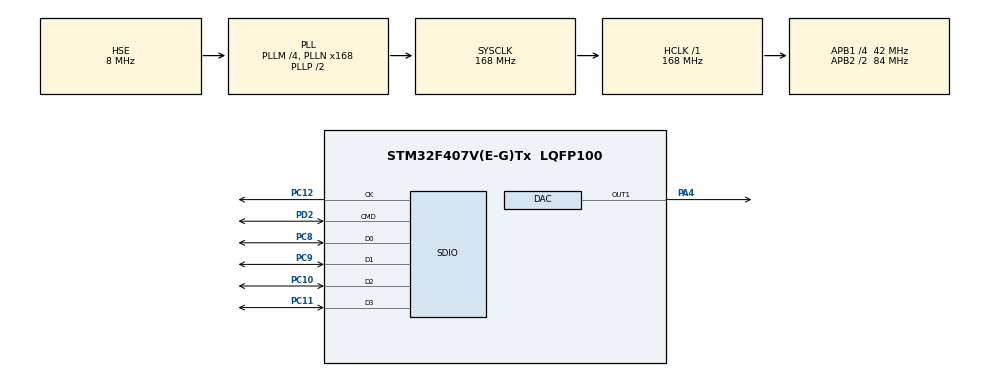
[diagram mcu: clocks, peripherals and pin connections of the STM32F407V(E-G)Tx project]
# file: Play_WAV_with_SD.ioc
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DAC.DAC_Trigger=DAC_TRIGGER_T6_TRGO
Dma.DAC1.0.Direction=DMA_MEMORY_TO_PERIPH
Dma.DAC1.0.FIFOMode=DMA_FIFOMODE_DISABLE
Dma.DAC1.0.Instance=DMA1_Stream5
Dma.DAC1.0.MemDataAlignment=DMA_MDATAALIGN_HALFWORD
Dma.DAC1.0.MemInc=DMA_MINC_ENABLE
Dma.DAC1.0.Mode=DMA_NORMAL
Dma.DAC1.0.PeriphDataAlignment=DMA_PDATAALIGN_HALFWORD
Dma.DAC1.0.PeriphInc=DMA_PINC_DISABLE
Dma.DAC1.0.Priority=DMA_PRIORITY_LOW
Dma.Request0=DAC1
Dma.Request1=SDIO_RX
Dma.SDIO_RX.1.Direction=DMA_PERIPH_TO_MEMORY
Dma.SDIO_RX.1.FIFOMode=DMA_FIFOMODE_ENABLE
Dma.SDIO_RX.1.FIFOThreshold=DMA_FIFO_THRESHOLD_FULL
Dma.SDIO_RX.1.Instance=DMA2_Stream3
Dma.SDIO_RX.1.MemBurst=DMA_MBURST_INC4
Dma.SDIO_RX.1.MemDataAlignment=DMA_MDATAALIGN_WORD
Dma.SDIO_RX.1.MemInc=DMA_MINC_ENABLE
Dma.SDIO_RX.1.Mode=DMA_PFCTRL
Dma.SDIO_RX.1.PeriphBurst=DMA_PBURST_INC4
Dma.SDIO_RX.1.PeriphDataAlignment=DMA_PDATAALIGN_WORD
Dma.SDIO_RX.1.PeriphInc=DMA_PINC_DISABLE
Dma.SDIO_RX.1.Priority=DMA_PRIORITY_LOW
FATFS.USE_DMA_CODE_SD=1
FATFS._MAX_SS=4096
FATFS._USE_LFN=3
Mcu.Family=STM32F4
Mcu.Name=STM32F407V(E-G)Tx
Mcu.Package=LQFP100
NVIC.DMA1_Stream5_IRQn=true\:1\:0\:true\:false\:true\:false
NVIC.DMA2_Stream3_IRQn=true\:0\:0\:false\:false\:true\:false
NVIC.PriorityGroup=NVIC_PRIORITYGROUP_4
NVIC.SDIO_IRQn=true\:0\:0\:false\:false\:true\:true
PA13.Mode=Serial_Wire
PA13.Signal=SYS_JTMS-SWDIO
PA14.Mode=Serial_Wire
PA14.Signal=SYS_JTCK-SWCLK
PA4.Signal=COMP_DAC1_group
PC10.Mode=SD_4_bits_Wide_bus
PC10.Signal=SDIO_D2
PC11.Mode=SD_4_bits_Wide_bus
PC11.Signal=SDIO_D3
PC12.Mode=SD_4_bits_Wide_bus
PC12.Signal=SDIO_CK
PC8.Mode=SD_4_bits_Wide_bus
PC8.Signal=SDIO_D0
PC9.Mode=SD_4_bits_Wide_bus
PC9.Signal=SDIO_D1
PD2.Mode=SD_4_bits_Wide_bus
PD2.Signal=SDIO_CMD
PH0-OSC_IN.Mode=HSE-External-Oscillator
PH0-OSC_IN.Signal=RCC_OSC_IN
PH1-OSC_OUT.Mode=HSE-External-Oscillator
PH1-OSC_OUT.Signal=RCC_OSC_OUT
ProjectManager.HeapSize=0x400
ProjectManager.StackSize=0x800
ProjectManager.TargetToolchain=MDK-ARM V5
RCC.48MHZClocksFreq_Value=48000000
RCC.AHBFreq_Value=168000000
RCC.APB1CLKDivider=RCC_HCLK_DIV4
RCC.APB1Freq_Value=42000000
RCC.APB1TimFreq_Value=84000000
RCC.APB2CLKDivider=RCC_HCLK_DIV2
RCC.APB2Freq_Value=84000000
RCC.APB2TimFreq_Value=168000000
RCC.CortexFreq_Value=168000000
RCC.HCLKFreq_Value=168000000
RCC.HSE_VALUE=8000000
RCC.HSI_VALUE=16000000
RCC.LSE_VALUE=32768
RCC.PLLM=4
RCC.PLLN=168
RCC.PLLQ=7
RCC.PLLSourceVirtual=RCC_PLLSOURCE_HSE
RCC.SYSCLKFreq_VALUE=168000000
RCC.SYSCLKSource=RCC_SYSCLKSOURCE_PLLCLK
RCC.VCOOutputFreq_Value=336000000
SH.COMP_DAC1_group.0=DAC_OUT1,DAC_OUT1
TIM6.Period=525-1
TIM6.Prescaler=5-1
TIM6.TIM_MasterOutputTrigger=TIM_TRGO_UPDATE
VP_FATFS_VS_SDIO.Mode=SDIO
VP_TIM6_VS_ClockSourceINT.Mode=Enable_Timer
board=custom

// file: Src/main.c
/**
  ******************************************************************************
  * @file           : main.c
  * @brief          : Main program body
  ******************************************************************************
  * This notice applies to any and all portions of this file
  * that are not between comment pairs USER CODE BEGIN and
  * USER CODE END. Other portions of this file, whether
  * inserted by the user or by software development tools
  * are owned by their respective copyright owners.
  *
  * Copyright (c) 2019 STMicroelectronics International N.V.
  * All rights reserved.
  *
  * Redistribution and use in source and binary forms, with or without
  * modification, are permitted, provided that the following conditions are met:
  *
  * 1. Redistribution of source code must retain the above copyright notice,
  *    this list of conditions and the following disclaimer.
  * 2. Redistributions in binary form must reproduce the above copyright notice,
  *    this list of conditions and the following disclaimer in the documentation
  *    and/or other materials provided with the distribution.
  * 3. Neither the name of STMicroelectronics nor the names of other
  *    contributors to this software may be used to endorse or promote products
  *    derived from this software without specific written permission.
  * 4. This software, including modifications and/or derivative works of this
  *    software, must execute solely and exclusively on microcontroller or
  *    microprocessor devices manufactured by or for STMicroelectronics.
  * 5. Redistribution and use of this software other than as permitted under
  *    this license is void and will automatically terminate your rights under
  *    this license.
  *
  * THIS SOFTWARE IS PROVIDED BY STMICROELECTRONICS AND CONTRIBUTORS "AS IS"
  * AND ANY EXPRESS, IMPLIED OR STATUTORY WARRANTIES, INCLUDING, BUT NOT
  * LIMITED TO, THE IMPLIED WARRANTIES OF MERCHANTABILITY, FITNESS FOR A
  * PARTICULAR PURPOSE AND NON-INFRINGEMENT OF THIRD PARTY INTELLECTUAL PROPERTY
  * RIGHTS ARE DISCLAIMED TO THE FULLEST EXTENT PERMITTED BY LAW. IN NO EVENT
  * SHALL STMICROELECTRONICS OR CONTRIBUTORS BE LIABLE FOR ANY DIRECT, INDIRECT,
  * INCIDENTAL, SPECIAL, EXEMPLARY, OR CONSEQUENTIAL DAMAGES (INCLUDING, BUT NOT
  * LIMITED TO, PROCUREMENT OF SUBSTITUTE GOODS OR SERVICES; LOSS OF USE, DATA,
  * OR PROFITS; OR BUSINESS INTERRUPTION) HOWEVER CAUSED AND ON ANY THEORY OF
  * LIABILITY, WHETHER IN CONTRACT, STRICT LIABILITY, OR TORT (INCLUDING
  * NEGLIGENCE OR OTHERWISE) ARISING IN ANY WAY OUT OF THE USE OF THIS SOFTWARE,
  * EVEN IF ADVISED OF THE POSSIBILITY OF SUCH DAMAGE.
  *
  ******************************************************************************
  */
#include "main.h"
#include "stm32f4xx_hal.h"
#include "dac.h"
#include "dma.h"
#include "fatfs.h"
#include "sdio.h"
#include "tim.h"
#include "gpio.h"

/* USER CODE BEGIN Includes */
#include "wave.h"

/* USER CODE END Includes */

/* USER CODE BEGIN PV */

/* Private variables ---------------------------------------------------------*/

/* USER CODE END PV */

void SystemClock_Config(void);

/* USER CODE BEGIN PFP */
/* Private function prototypes -----------------------------------------------*/

/* USER CODE END PFP */

int main(void)
{

  /* MCU Configuration----------------------------------------------------------*/

  /* Reset of all peripherals, Initializes the Flash interface and the Systick. */
  HAL_Init();

  /* Configure the system clock */
  SystemClock_Config();

  /* Initialize all configured peripherals */
  MX_GPIO_Init();
  MX_DMA_Init();
  MX_TIM6_Init();
  MX_DAC_Init();
  MX_SDIO_SD_Init();
  MX_FATFS_Init();
  /* USER CODE BEGIN 2 */

	char *my_file_name_0 = "crow2.wav";
	char *my_file_name_1 = "Crow.wav";
	char *my_file_name_2 = "1999.wav";
	char *my_file_name_3 = "1kHz_16000Hz_16bit_mono.wav";
	char *my_file_name_4 = "nice-work.wav";
	play_wave(my_file_name_4);
  /* USER CODE END 2 */

  /* Infinite loop */
  while (1)
  {

  }

}

void SystemClock_Config(void)
{

  RCC_OscInitTypeDef RCC_OscInitStruct;
  RCC_ClkInitTypeDef RCC_ClkInitStruct;

    /**Configure the main internal regulator output voltage
    */
  __HAL_RCC_PWR_CLK_ENABLE();

  __HAL_PWR_VOLTAGESCALING_CONFIG(PWR_REGULATOR_VOLTAGE_SCALE1);

    /**Initializes the CPU, AHB and APB busses clocks
    */
  RCC_OscInitStruct.OscillatorType = RCC_OSCILLATORTYPE_HSE;
  RCC_OscInitStruct.HSEState = RCC_HSE_ON;
  RCC_OscInitStruct.PLL.PLLState = RCC_PLL_ON;
  RCC_OscInitStruct.PLL.PLLSource = RCC_PLLSOURCE_HSE;
  RCC_OscInitStruct.PLL.PLLM = 4;
  RCC_OscInitStruct.PLL.PLLN = 168;
  RCC_OscInitStruct.PLL.PLLP = RCC_PLLP_DIV2;
  RCC_OscInitStruct.PLL.PLLQ = 7;
  if (HAL_RCC_OscConfig(&RCC_OscInitStruct) != HAL_OK)
  {
    _Error_Handler(__FILE__, __LINE__);
  }

    /**Initializes the CPU, AHB and APB busses clocks
    */
  RCC_ClkInitStruct.ClockType = RCC_CLOCKTYPE_HCLK|RCC_CLOCKTYPE_SYSCLK
                              |RCC_CLOCKTYPE_PCLK1|RCC_CLOCKTYPE_PCLK2;
  RCC_ClkInitStruct.SYSCLKSource = RCC_SYSCLKSOURCE_PLLCLK;
  RCC_ClkInitStruct.AHBCLKDivider = RCC_SYSCLK_DIV1;
  RCC_ClkInitStruct.APB1CLKDivider = RCC_HCLK_DIV4;
  RCC_ClkInitStruct.APB2CLKDivider = RCC_HCLK_DIV2;

  if (HAL_RCC_ClockConfig(&RCC_ClkInitStruct, FLASH_LATENCY_5) != HAL_OK)
  {
    _Error_Handler(__FILE__, __LINE__);
  }

    /**Configure the Systick interrupt time
    */
  HAL_SYSTICK_Config(HAL_RCC_GetHCLKFreq()/1000);

    /**Configure the Systick
    */
  HAL_SYSTICK_CLKSourceConfig(SYSTICK_CLKSOURCE_HCLK);

  /* SysTick_IRQn interrupt configuration */
  HAL_NVIC_SetPriority(SysTick_IRQn, 0, 0);
}

void _Error_Handler(char *file, int line)
{
  while(1)
  {
  }
}

/************************ (C) COPYRIGHT STMicroelectronics *****END OF FILE****/
